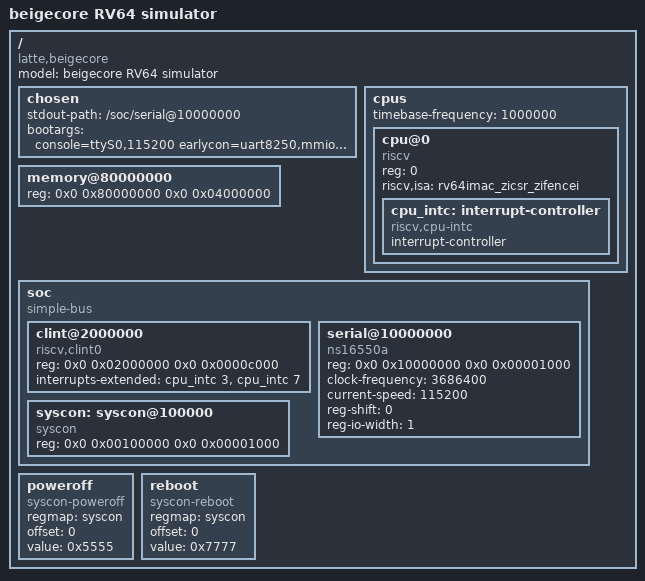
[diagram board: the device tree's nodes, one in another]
/dts-v1/;

/ {
    #address-cells = <2>;
    #size-cells = <2>;
    compatible = "latte,beigecore";
    model = "beigecore RV64 simulator";

    chosen {
        stdout-path = "/soc/serial@10000000";
        bootargs = "console=ttyS0,115200 earlycon=uart8250,mmio,0x10000000 rdinit=/bin/sh";
    };

    cpus {
        #address-cells = <1>;
        #size-cells = <0>;
        timebase-frequency = <1000000>;

        cpu@0 {
            device_type = "cpu";
            reg = <0>;
            status = "okay";
            compatible = "riscv";
            riscv,isa = "rv64imac_zicsr_zifencei";

            cpu_intc: interrupt-controller {
                #interrupt-cells = <1>;
                interrupt-controller;
                compatible = "riscv,cpu-intc";
            };
        };
    };

    memory@80000000 {
        device_type = "memory";
        reg = <0x0 0x80000000 0x0 0x04000000>;
    };

    soc {
        #address-cells = <2>;
        #size-cells = <2>;
        compatible = "simple-bus";
        ranges;

        clint@2000000 {
            compatible = "riscv,clint0";
            reg = <0x0 0x02000000 0x0 0x0000c000>;
            interrupts-extended = <&cpu_intc 3 &cpu_intc 7>;
        };

        serial@10000000 {
            compatible = "ns16550a";
            reg = <0x0 0x10000000 0x0 0x00001000>;
            clock-frequency = <3686400>;
            current-speed = <115200>;
            reg-shift = <0>;
            reg-io-width = <1>;
            status = "okay";
        };

        syscon: syscon@100000 {
            compatible = "syscon";
            reg = <0x0 0x00100000 0x0 0x00001000>;
        };
    };

    poweroff {
        compatible = "syscon-poweroff";
        regmap = <&syscon>;
        offset = <0>;
        value = <0x5555>;
    };

    reboot {
        compatible = "syscon-reboot";
        regmap = <&syscon>;
        offset = <0>;
        value = <0x7777>;
    };
};
